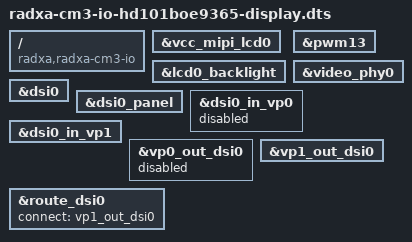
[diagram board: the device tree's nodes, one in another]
/dts-v1/;
/plugin/;

/ {
	compatible = "radxa,radxa-cm3-io", "rockchip,rk3566";

	fragment@0 {
		target = <&vcc_mipi_lcd0>;

		__overlay__ {
			status = "okay";
		};
	};

	fragment@1 {
		target = <&lcd0_backlight>;

		__overlay__ {
			status = "okay";
		};
	};

	fragment@2 {
		target = <&pwm13>;

		__overlay__ {
			status = "okay";
		};
	};

	fragment@3 {
		target = <&video_phy0>;

		__overlay__ {
			status = "okay";
		};
	};

	fragment@4 {
		target = <&dsi0>;

		__overlay__ {
			status = "okay";
		};
	};

	fragment@5 {
		target = <&dsi0_panel>;

		__overlay__ {
			status = "okay";
		};
	};

	fragment@6 {
		target = <&dsi0_in_vp0>;

		__overlay__ {
			status = "disabled";
		};
	};

	fragment@7 {
		target = <&dsi0_in_vp1>;

		__overlay__ {
			status = "okay";
		};
	};

	fragment@8 {
		target = <&vp0_out_dsi0>;

		__overlay__ {
			status = "disabled";
		};
	};

	fragment@9 {
		target = <&vp1_out_dsi0>;

		__overlay__ {
			status = "okay";
		};
	};

	fragment@10 {
		target = <&route_dsi0>;

		__overlay__ {
			status = "okay";
			connect = <&vp1_out_dsi0>;
		};
	};
};
